# RTS591x register map
Vendor: Realtek Semiconductor Corp.; Series: RTS591x Series; File version: 1.0
CPU: ARMV8MML r0p0, little endian, MPU, FPU, VTOR, 3 interrupt priority bits, 4 SAU regions
Registers are 32-bit, read-write, reset 0x0 unless marked. A register's access mark holds for its fields unless they carry their own. Offsets are from the block's base; [hi:lo] are bit positions; {n}, {i} and the like mark numbered series.

## DMA — DMA Controller
Base 0x4000B800
{0x0+0x58*i} SAR{i} (i=0..7) — SOURCE ADDRESS REGISTER
{0x8+0x58*i} DAR{i} (i=0..7) — DESTINATION ADDRESS REGISTER
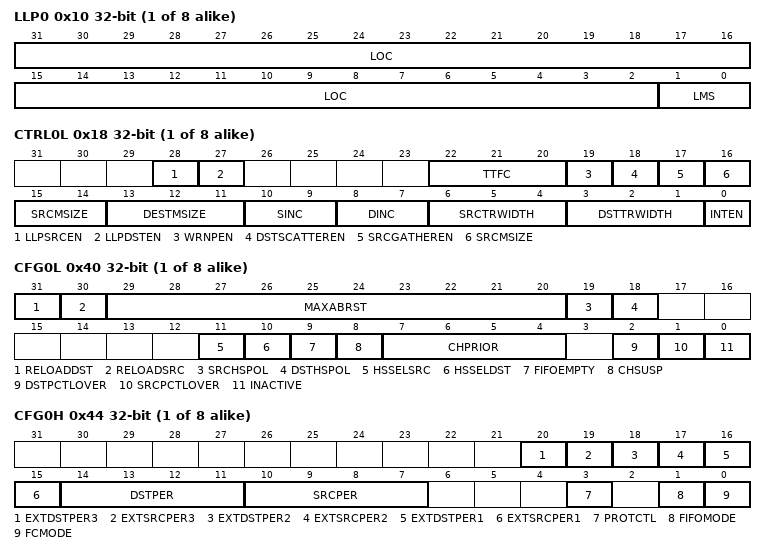
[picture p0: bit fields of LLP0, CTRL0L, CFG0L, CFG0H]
{0x10+0x58*i} LLP{i} (i=0..7) — LINKED LIST POINTER REGISTER
  [31:2] LOC — Starting Address In Memory
  [1:0] LMS — List Master Select
{0x18+0x58*i} CTRL{i}L (i=0..7) — CONTROL REGISTER LOW
  [28] LLPSRCEN — Block chanining is enabled on the source side only
    0=Disable src block chanining; 1=Enable src block chanining
  [27] LLPDSTEN — Block chanining is enabled on the destination side only
    0=Disable dst block chanining; 1=Enable dst block chanining
  [22:20] TTFC — Transfer Type and Flow Control
    0=M2M (Memory to Memory); 1=M2P (Memory to Peripheral); 2=P2M (Peripheral to Memory); 3=P2P (Peripheral to Peripheral)
  [19] WRNPEN — OCP non-posted write enable bit
    0=Disable non-posted write; 1=Enable non-posted write
  [18] DSTSCATTEREN — Destination scatter enable bit
    0=Disable gather; 1=Enable gather
  [17] SRCGATHEREN — Source gather enable bit
    0=DISABLE (Disable gather); 1=ENABLE (Enable gather)
  [16:14] SRCMSIZE — Source Burst Transaction Length
  [13:11] DESTMSIZE — Destination Burst Transaction Length
  [10:9] SINC — Source Address Increment
  [8:7] DINC — Destination Address Increment
  [6:4] SRCTRWIDTH — Source Transfer Width
  [3:1] DSTTRWIDTH — Destination Transfer Width
  [0] INTEN — Interrupt Enable Bit
    0=DISABLE (Disable interrup); 1=ENABLE (Enable interrup)
{0x1C+0x58*i} CTRL{i}H (i=0..7) — CONTROL REGISTER HIGH
  [31:0] BLOCKTS — Block Transfer Size
{0x40+0x58*i} CFG{i}L (i=0..7) — CONFIGURATION REGISTER LOW
  [31] RELOADDST — Automatic Destination Reload
  [30] RELOADSRC — Automatic Source Reload
  [29:20] MAXABRST — Maximum AXI Burst Length
  [19] SRCHSPOL — Source Handshaking Interface Polarity
  [18] DSTHSPOL — Destination Handshaking Interface Polarity
  [11] HSSELSRC — Source Software or Hardware Handshaking Select
  [10] HSSELDST — Destination Software or Hardware Handshaking Select
  [9] FIFOEMPTY ro — Indicates if there is data left in the channel FIFO
  [8] CHSUSP — Channel Suspend
  [7:4] CHPRIOR — Channel priority
  [2] DSTPCTLOVER ro — DMA destination bus protocol finish, indicating the current read command has finished
  [1] SRCPCTLOVER ro — DMA Source bus protocol finish, indicating the current read command has finished
  [0] INACTIVE ro — Indicates if the channel is inactive
{0x44+0x58*i} CFG{i}H (i=0..7) — CONFIGURATION REGISTER HIGH
  [20] EXTDSTPER3 — The extened 6th bit of DSTPER
  [19] EXTSRCPER3 — The extened 6th bit of SRCPER
  [18] EXTDSTPER2 — The extened 5th bit of DSTPER
  [17] EXTSRCPER2 — The extened 5th bit of SRCPER
  [16] EXTDSTPER1 — The extened 4th bit of DSTPER
  [15] EXTSRCPER1 — The extened 4th bit of SRCPER
  [14:11] DSTPER — Assigns a Hardware Handshaking Interface to The Destination of Channel
  [10:7] SRCPER — Assigns a Hardware Handshaking Interface to The Source of Channel
  [3] PROTCTL — Protection Control
  [1] FIFOMODE — FIFO Mode Select
  [0] FCMODE — Flow Control Mode
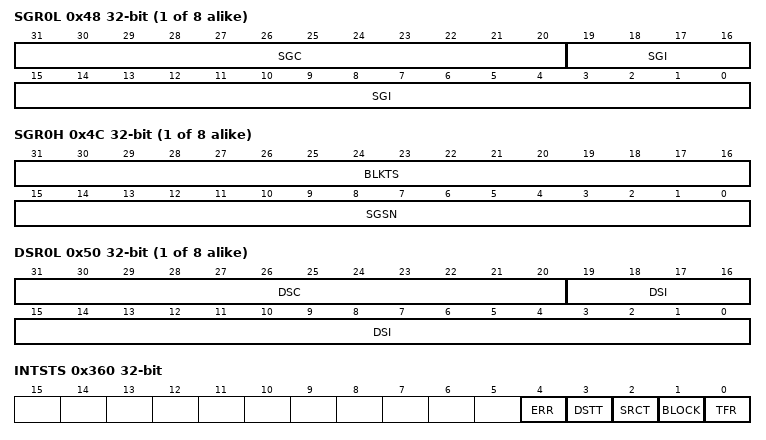
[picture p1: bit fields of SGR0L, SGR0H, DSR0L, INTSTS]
{0x48+0x58*i} SGR{i}L (i=0..7) — SOURCE GATHER REGISTER LOW
  [31:20] SGC — Source Gather Count
  [19:0] SGI — Source Gather Interval
{0x4C+0x58*i} SGR{i}H (i=0..7) — SOURCE GATHER REGISTER HIGH
  [31:16] BLKTS — Block Transfer Size
  [15:0] SGSN — Source Gather Circular Streaming Number
{0x50+0x58*i} DSR{i}L (i=0..7) — DESTINATION SCATTER REGISTER LOW
  [31:20] DSC — Destination Scatter Count
  [19:0] DSI — Destination Scatter Interval
{0x54+0x58*i} DSR{i}H (i=0..7) — DESTINATION SCATTER REGISTER HIGH
  [4:0] DSI — Destination Scatter Circular Streaming Number
0x2C0 RAWTFR — RAW STATUS FOR INTTFR INTERRUPT REGISTER
0x2C8 RAWBLOCK — RAW STATUS FOR INTBLOCK REGISTER
0x2D0 RAWSRCTRAN — RAW STATUS FOR INTSRCTRAN INTERRUPT REGISTER
0x2D8 RAWDSTTRAN — RAW STATUS FOR INTDSTTRAN INTERRUPT REGISTER
0x2E0 RAWERR — RAW STATUS FOR INTERR INTERRUPT REGISTER
0x2E8 STSTFR — INTERRUPT STATUS FOR INTTFR INTERRUPT REGISTER
0x2F0 STSBLOCK — INTERRUPT STATUS FOR INTBLOCK REGISTER
0x2F8 STSSRCTRAN — INTERRUPT STATUS FOR INTSRCTRAN INTERRUPT REGISTER
0x300 STSDSTTRAN — INTERRUPT STATUS FOR INTDSTTRAN INTERRUPT REGISTER
0x308 STSERR — INTERRUPT STATUS FOR INTERR INTERRUPT REGISTER
0x310 MSKTFRL — MASK FOR INTTFR INTERRUPT REGISTER LOW
0x314 MSKTFRH — MASK FOR INTTFR INTERRUPT REGISTER HIGH
0x318 MSKBLOCKL — MASK FOR INTBLOCK REGISTER LOW
0x31C MSKBLOCKH — MASK FOR INTBLOCK REGISTER HIGH
0x320 MSKSRCTRANL — MASK FOR INTSRCTRAN INTERRUPT REGISTER LOW
0x324 MSKSRCTRANH — MASK FOR INTSRCTRAN INTERRUPT REGISTER HIGH
0x328 MSKDSTTRANL — MASK FOR INTDSTTRAN INTERRUPT REGISTER LOW
0x32C MSKDSTTRANH — MASK FOR INTDSTTRAN INTERRUPT REGISTER HIGH
0x330 MSKERRL — MASK FOR INTERR INTERRUPT REGISTER LOW
0x334 MSKERRH — MASK FOR INTERR INTERRUPT REGISTER HIGH
0x338 CLRTFR — CLEAR INTERRUPT STATUS FOR INTTFR INTERRUPT REGISTER
0x340 CLRBLOCK — CLEAR INTERRUPT STATUS FOR INTBLOCK REGISTER
0x348 CLRSRCTRAN — CLEAR INTERRUPT STATUS FOR INTSRCTRAN INTERRUPT REGISTER
0x350 CLRDSTTRAN — CLEAR INTERRUPT STATUS FOR INTDSTTRAN INTERRUPT REGISTER
0x358 CLRERR — CLEAR INTERRUPT STATUS FOR INTERR INTERRUPT REGISTER
0x360 INTSTS ro — COMBINED INTERRUPT SATAUS REGISTER
  [4] ERR — OR of The Contents of StatusErr Register
  [3] DSTT — OR of The Contents of StatusDst Register
  [2] SRCT — OR of The Contents of StatusSrcTran Register
  [1] BLOCK — OR of The Contents of StatusBlock Register
  [0] TFR — OR of The Contents of StatusTfr Register
0x398 CONF — CONFIGURATION REGISTER
  [0] EN — Enable DMA Controller
    0=DISABLE (Disable DMA Controller); 1=ENABLE (Enable DMA Controller)
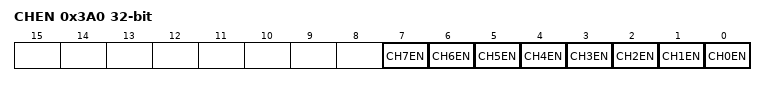
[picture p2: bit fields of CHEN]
0x3A0 CHEN — CHANNEL ENABLE REGISTER
  [n] CH{n}EN (n=0..7) — Enables DMA Channel
    0=DISABLE (Dsiable DMA Channel); 1=ENABLE (Enables DMA Channel)

## Notices in the file
The license belong to Realtek Semiconductor Corp. All the rights reserved.
